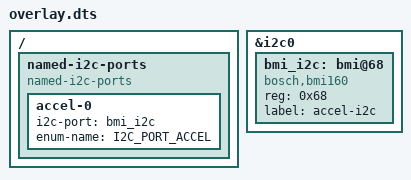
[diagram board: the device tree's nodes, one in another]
/* Copyright 2020 The Chromium OS Authors. All rights reserved.
 * Use of this source code is governed by a BSD-style license that can be
 * found in the LICENSE file.
 */

/ {
	named-i2c-ports {
		compatible = "named-i2c-ports";
		accel-0 {
			i2c-port = <&bmi_i2c>;
			enum-name = "I2C_PORT_ACCEL";
		};
	};
};

&i2c0 {
	bmi_i2c: bmi@68 {
		compatible = "bosch,bmi160";
		reg = <0x68>;
		label = "accel-i2c";
	};
};
